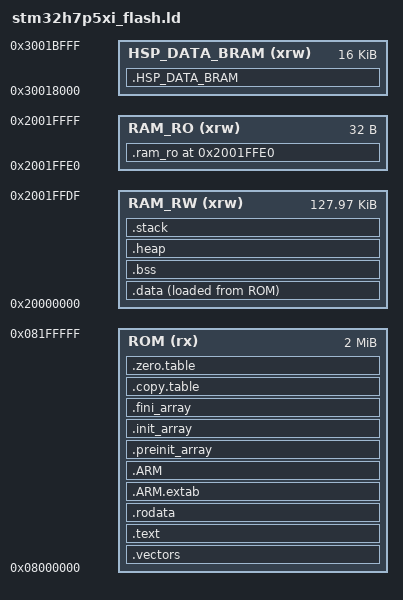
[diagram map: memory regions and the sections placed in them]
/**
******************************************************************************
* @file    stm32h7p5xi_flash.ld
* @brief   Linker File
******************************************************************************
* @attention
*
* Copyright (c) 2026 STMicroelectronics.
* All rights reserved.
*
* This software is licensed under terms that can be found in the LICENSE file
* in the root directory of this software component.
* If no LICENSE file comes with this software, it is provided AS-IS.
*
******************************************************************************
*/

/* Entry Point */
ENTRY(Reset_Handler)

HEAP_SIZE = 0x200;
STACK_SIZE = 0x400;


MEMORY
{
  ROM (rx) : org = 0x8000000, len = 0x200000
  RAM_RW (xrw) : org = 0x20000000, len = 0x1FFE0
  RAM_RO (xrw) : org = 0x2001FFE0, len = 0x20
  HSP_DATA_BRAM (xrw) : org = 0x30018000, len = 0x4000
}

SECTIONS
{
  .vectors :
  {
    . = ALIGN(8);
    KEEP(*(.vectors));
    . = ALIGN(8);
  } > ROM

  .text :
  {
    . = ALIGN(8);
    *(.text);
    *(.text*);
    *(.glue_7);
    *(.glue_7t);
    *(.eh_frame);
    KEEP (*(.init));
    KEEP (*(.fini));
    . = ALIGN(8);
    _etext = .;
  } > ROM

  .rodata :
  {
    . = ALIGN(8);
    *(.rodata);
    *(.rodata*);
    . = ALIGN(8);
  } > ROM

  .ARM.extab (READONLY) :
  {
    . = ALIGN(8);
    *(.ARM.extab* .gnu.linkonce.armextab.*)
    . = ALIGN(8);
  } > ROM

  .ARM (READONLY) :
  {
    . = ALIGN(8);
    __exidx_start = .;
    *(.ARM.exidx*);
    __exidx_end = .;
    . = ALIGN(8);
  } > ROM

  .preinit_array (READONLY) :
  {
    . = ALIGN(8);
    PROVIDE_HIDDEN (__preinit_array_start = .);
    KEEP (*(.preinit_array*));
    PROVIDE_HIDDEN (__preinit_array_end = .);
    . = ALIGN(8);
  } > ROM

  .init_array (READONLY) :
  {
    . = ALIGN(8);
    PROVIDE_HIDDEN (__init_array_start = .);
    KEEP (*(SORT(.init_array.*)));
    KEEP (*(.init_array*));
    PROVIDE_HIDDEN (__init_array_end = .);
    . = ALIGN(8);
  } > ROM

  .fini_array (READONLY) :
  {
    . = ALIGN(8);
    PROVIDE_HIDDEN (__fini_array_start = .);
    KEEP (*(SORT(.fini_array.*)));
    KEEP (*(.fini_array*));
    PROVIDE_HIDDEN (__fini_array_end = .);
    . = ALIGN(8);
  } > ROM

  .copy.table (READONLY) :
  {
    . = ALIGN(8);
    __copy_table_start__ = .;
    LONG(LOADADDR(.data));
    LONG (ADDR(.data));
    LONG (SIZEOF(.data) / 4);
    __copy_table_end__ = .;
  } > ROM

  .zero.table (READONLY) :
  {
    . = ALIGN(8);
    __zero_table_start__ = .;
    LONG (ADDR(.bss));
    LONG (SIZEOF(.bss) / 4);
    __zero_table_end__ = .;
  } > ROM

  .data :
  {
    . = ALIGN(8);
    _sidata = LOADADDR(.data);
    __data_start__ = .;
    _sdata = .;
    *(.data);
    *(.data*);
    . = ALIGN(8);
    _edata = .;
  } > RAM_RW AT> ROM

  .bss :
  {
    . = ALIGN(8);
    _sbss = .;
    __bss_start__ = _sbss;
    *(.bss);
    *(.bss*);
    *(COMMON);
    . = ALIGN(8);
    _ebss = .;
    __bss_end__ = _ebss;
  } > RAM_RW

  .heap (NOLOAD) :
  {
    . = ALIGN(8);
    __end__ = .;
    PROVIDE (end = .);
    _heap_start = .;
    . += HEAP_SIZE;
    . = ALIGN(8);
    _heap_end = .;
    __HeapLimit = .;
  } > RAM_RW

  .stack (NOLOAD) :
  {
    . = ALIGN(8);
    __StackLimit = .;
    . += STACK_SIZE;
    . = ALIGN(8);
    __StackTop = .;
    _estack = .;
    __stack = .;
  } > RAM_RW

  .HSP_DATA_BRAM :
  {
    __HSP_DATA_BRAM_start_ = .;
    . = ALIGN(8);
    *(.HSP_DATA_BRAM);
    *(.HSP_DATA_BRAM*);
    . = ALIGN(8);
    __HSP_DATA_BRAM_end_ = .;
  } > HSP_DATA_BRAM

  .ram_ro 0x2001FFE0 (NOLOAD) :
  {
    *(.ram_ro)
  } > RAM_RO

  /DISCARD/ :
  {
    libc.a ( * )
    libm.a ( * )
    libgcc.a ( * )
  }

  .ARM.attributes 0 :
  {
    *(.ARM.attributes)
  }
}
